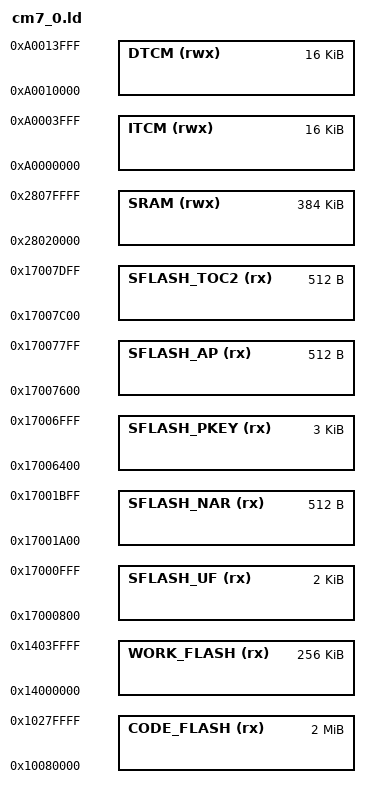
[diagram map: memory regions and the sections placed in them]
ENTRY(_start)

MEMORY
{
    CODE_FLASH (rx)  : ORIGIN = 0x10080000, LENGTH = 2048K
    SRAM       (rwx) : ORIGIN = 0x28020000, LENGTH = 384K
    ITCM       (rwx) : ORIGIN = 0xA0000000, LENGTH = 16K
    DTCM       (rwx) : ORIGIN = 0xA0010000, LENGTH = 16K
    WORK_FLASH (rx)  : ORIGIN = 0x14000000, LENGTH = 256K
    SFLASH_UF  (rx)  : ORIGIN = 0x17000800, LENGTH = 2K
    SFLASH_NAR (rx)  : ORIGIN = 0x17001A00, LENGTH = 512
    SFLASH_PKEY (rx) : ORIGIN = 0x17006400, LENGTH = 3K
    SFLASH_AP  (rx)  : ORIGIN = 0x17007600, LENGTH = 512
    SFLASH_TOC2 (rx) : ORIGIN = 0x17007C00, LENGTH = 512
}

__cm7_bss_start = 0x2802B848;

INCLUDE cm7_common.ld
